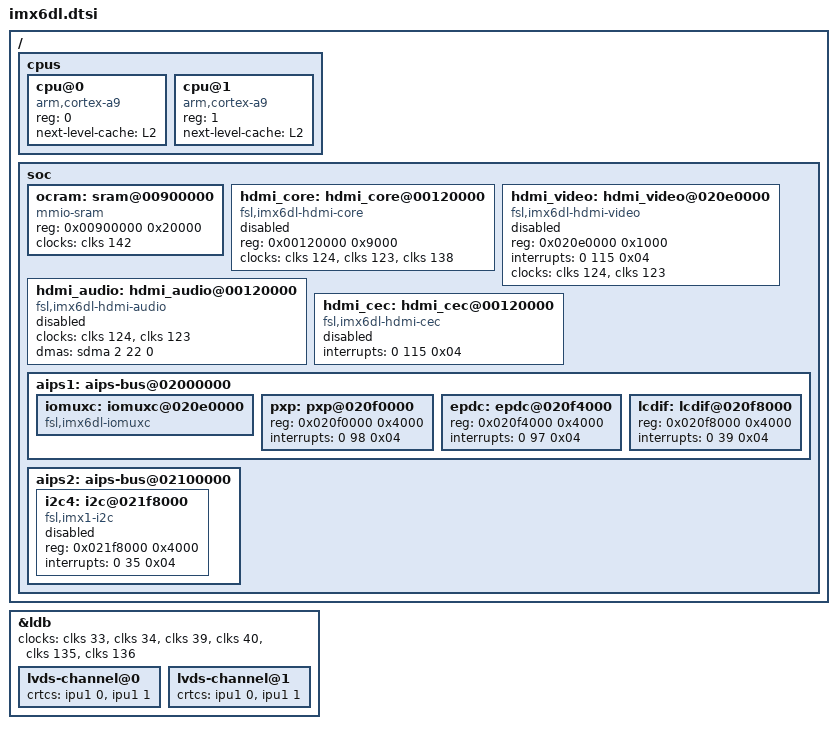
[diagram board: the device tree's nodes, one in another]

/*
 * Copyright 2013 Freescale Semiconductor, Inc.
 *
 * This program is free software; you can redistribute it and/or modify
 * it under the terms of the GNU General Public License version 2 as
 * published by the Free Software Foundation.
 *
 */

#include "imx6dl-pinfunc.h"
#include "imx6qdl.dtsi"

/ {
	cpus {
		#address-cells = <1>;
		#size-cells = <0>;

		cpu@0 {
			compatible = "arm,cortex-a9";
			device_type = "cpu";
			reg = <0>;
			next-level-cache = <&L2>;
		};

		cpu@1 {
			compatible = "arm,cortex-a9";
			device_type = "cpu";
			reg = <1>;
			next-level-cache = <&L2>;
		};
	};

	soc {
		ocram: sram@00900000 {
			compatible = "mmio-sram";
			reg = <0x00900000 0x20000>;
			clocks = <&clks 142>;
		};

		hdmi_core: hdmi_core@00120000 {
			compatible = "fsl,imx6dl-hdmi-core";
			reg = <0x00120000 0x9000>;
			clocks = <&clks 124>, <&clks 123>, <&clks 138>;
			clock-names = "hdmi_isfr", "hdmi_iahb", "mipi_core";
			status = "disabled";
		};

		hdmi_video: hdmi_video@020e0000 {
			compatible = "fsl,imx6dl-hdmi-video";
			reg =  <0x020e0000 0x1000>;
			reg-names = "hdmi_gpr";
			interrupts = <0 115 0x04>;
			clocks = <&clks 124>, <&clks 123>;
			clock-names = "hdmi_isfr", "hdmi_iahb";
			status = "disabled";
		};

		hdmi_audio: hdmi_audio@00120000 {
			compatible = "fsl,imx6dl-hdmi-audio";
			clocks = <&clks 124>, <&clks 123>;
			clock-names = "hdmi_isfr", "hdmi_iahb";
			dmas = <&sdma 2 22 0>;
			dma-names = "tx";
			status = "disabled";
		};

		hdmi_cec: hdmi_cec@00120000 {
			compatible = "fsl,imx6dl-hdmi-cec";
			interrupts = <0 115 0x04>;
			status = "disabled";
		};

		aips1: aips-bus@02000000 {
			iomuxc: iomuxc@020e0000 {
				compatible = "fsl,imx6dl-iomuxc";
			};

			pxp: pxp@020f0000 {
				reg = <0x020f0000 0x4000>;
				interrupts = <0 98 0x04>;
			};

			epdc: epdc@020f4000 {
				reg = <0x020f4000 0x4000>;
				interrupts = <0 97 0x04>;
			};

			lcdif: lcdif@020f8000 {
				reg = <0x020f8000 0x4000>;
				interrupts = <0 39 0x04>;
			};
		};

		aips2: aips-bus@02100000 {
			i2c4: i2c@021f8000 {
				#address-cells = <1>;
				#size-cells = <0>;
				compatible = "fsl,imx1-i2c";
				reg = <0x021f8000 0x4000>;
				interrupts = <0 35 0x04>;
				status = "disabled";
			};
		};
	};
};

&ldb {
	clocks = <&clks 33>, <&clks 34>,
		 <&clks 39>, <&clks 40>,
		 <&clks 135>, <&clks 136>;
	clock-names = "di0_pll", "di1_pll",
		      "di0_sel", "di1_sel",
		      "di0", "di1";

	lvds-channel@0 {
		crtcs = <&ipu1 0>, <&ipu1 1>;
	};

	lvds-channel@1 {
		crtcs = <&ipu1 0>, <&ipu1 1>;
	};
};
